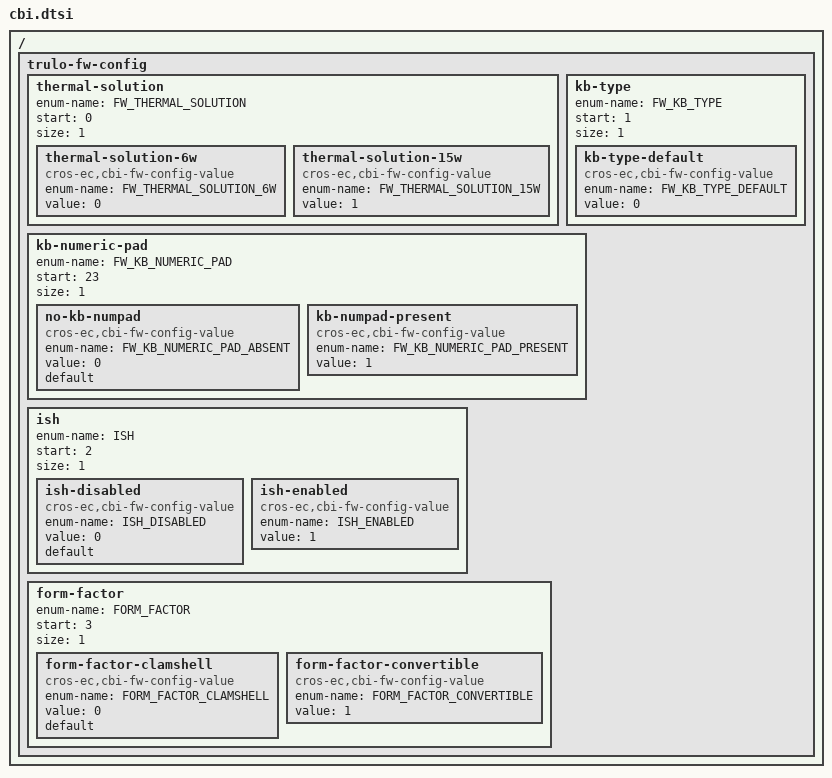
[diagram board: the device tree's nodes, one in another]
/* Copyright 2025 The ChromiumOS Authors
 * Use of this source code is governed by a BSD-style license that can be
 * found in the LICENSE file.
 */

/ {
/* Pujjolo-specific fw_config fields. */
	trulo-fw-config {
		/*
		 * FW_CONFIG field to defined for THERMAL SOLUTION.
		 */
		thermal-solution {
			enum-name = "FW_THERMAL_SOLUTION";
			start = <0>;
			size = <1>;

			thermal-solution-6w {
				compatible = "cros-ec,cbi-fw-config-value";
				enum-name = "FW_THERMAL_SOLUTION_6W";
				value = <0>;
			};
			thermal-solution-15w {
				compatible = "cros-ec,cbi-fw-config-value";
				enum-name = "FW_THERMAL_SOLUTION_15W";
				value = <1>;
			};
		};

		/*
		 * FW_CONFIG field to defined for KB TYPE.
		 */
		kb-type {
			enum-name = "FW_KB_TYPE";
			start = <1>;
			size = <1>;

			kb-type-default {
				compatible = "cros-ec,cbi-fw-config-value";
				enum-name = "FW_KB_TYPE_DEFAULT";
				value = <0>;
			};
		};

		/*
		 * FW_CONFIG field to indicate which keyboard numeric
		 * pad should be used.
		 */
		kb-numeric-pad {
			enum-name = "FW_KB_NUMERIC_PAD";
			start = <23>;
			size = <1>;

			no-kb-numpad {
				compatible = "cros-ec,cbi-fw-config-value";
				enum-name = "FW_KB_NUMERIC_PAD_ABSENT";
				value = <0>;
				default;
			};
			kb-numpad-present {
				compatible = "cros-ec,cbi-fw-config-value";
				enum-name = "FW_KB_NUMERIC_PAD_PRESENT";
				value = <1>;
			};
		};

		ish {
			enum-name = "ISH";
			start = <2>;
			size = <1>;

			ish-disabled {
				compatible = "cros-ec,cbi-fw-config-value";
				enum-name = "ISH_DISABLED";
				value = <0>;
				default;
			};
			ish-enabled {
				compatible = "cros-ec,cbi-fw-config-value";
				enum-name = "ISH_ENABLED";
				value = <1>;
			};
		};

		form-factor {
			enum-name = "FORM_FACTOR";
			start = <3>;
			size = <1>;

			form-factor-clamshell {
				compatible = "cros-ec,cbi-fw-config-value";
				enum-name = "FORM_FACTOR_CLAMSHELL";
				value = <0>;
				default;
			};
			form-factor-convertible {
				compatible = "cros-ec,cbi-fw-config-value";
				enum-name = "FORM_FACTOR_CONVERTIBLE";
				value = <1>;
			};
		};
	};
};
